# ATSAMRH707F18A register map
Vendor: Microchip Technology; Series: SAMRH707; File version: 0
CPU: CM7 r1p1, little endian, MPU, FPU, 3 interrupt priority bits
Registers are 32-bit, read-write, reset 0x0 unless marked. A register's access mark holds for its fields unless they carry their own. Offsets are from the block's base; [hi:lo] are bit positions; {n}, {i} and the like mark numbered series; 'fields as' and 'values as' point back to an identical list.

## TCMECC
Base 0x40100400; register names take the prefix TCMECC_
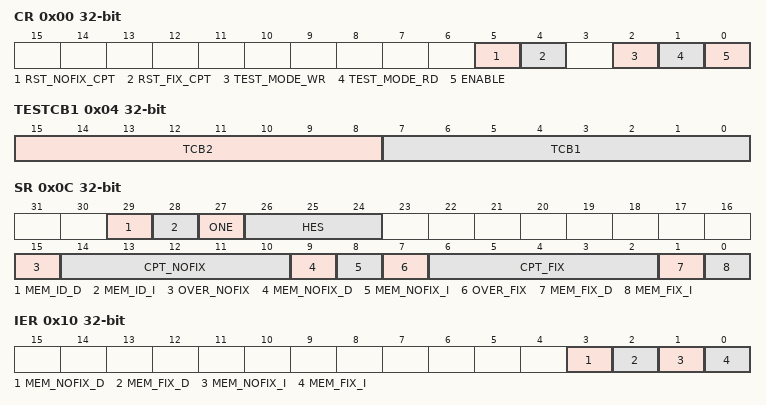
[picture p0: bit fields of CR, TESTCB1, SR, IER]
0x00 CR — TCMECC Control Register
  [5] RST_NOFIX_CPT — reset the un-fixable error counter
  [4] RST_FIX_CPT — reset the fixable error counter
  [2] TEST_MODE_WR — test mode of ECC protection - write mode
  [1] TEST_MODE_RD — test mode of ECC protection - read mode
  [0] ENABLE — ECC protection enable
0x04 TESTCB1 — TCMECC Test mode register 1
  [15:8] TCB2 — test check bit (8 bit)
  [7:0] TCB1 — test check bit (8 bit)
0x0C SR ro — TCMECC Status register
  [29] MEM_ID_D — memory identification number
  [28] MEM_ID_I — memory identification number
  [27] ONE
  [26:24] HES — Hardware Error Size
  [15] OVER_NOFIX — counter overflow
  [14:10] CPT_NOFIX — 5 bits counter
  [9] MEM_NOFIX_D — Un-fixable error status in data memory
  [8] MEM_NOFIX_I — Un-fixable error status in instruction memory
  [7] OVER_FIX — counter overflow
  [6:2] CPT_FIX — 5 bits counter
  [1] MEM_FIX_D — Fixable error status in data memory
  [0] MEM_FIX_I — Fixable error status in instruction memory
0x10 IER wo — TCMECC Interrupt Enable Register
  [3] MEM_NOFIX_D — Un-fixable error on data
  [2] MEM_FIX_D — Fixable error on data
  [1] MEM_NOFIX_I — Un-fixable error on instruction
  [0] MEM_FIX_I — Fixable error on instruction
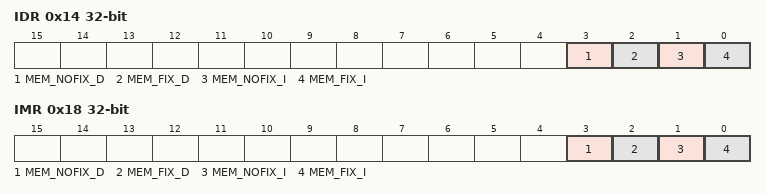
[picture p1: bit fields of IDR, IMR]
0x14 IDR wo — TCMECC Interrupt Disable Register
  [3] MEM_NOFIX_D — un-fixable error on data
  [2] MEM_FIX_D — fixable error on data
  [1] MEM_NOFIX_I — un-fixable error on instruction
  [0] MEM_FIX_I — fixable error on instruction
0x18 IMR ro — TCMECC Interrupt Mask Register
  fields as IDR
0x1C FAILAR ro — TCMECC Fail address register
  [31:0] ADDRESS — address of the error detected (refers to instruction memory)
0x20 FAILARD ro — TCMECC Fail address register data
  [31:0] ADDRESS — address of the error detected
0x24 FAILDR ro — TCMECC Fail data register
  [31:0] DATA — data of the error detected (refers to instruction memory)
0x28 FAILDRD ro — TCMECC Fail data register data
  fields as FAILDR

## TRNG — True Random Number Generator
Base 0x40090000; register names take the prefix TRNG_
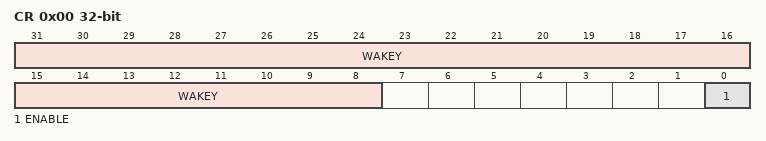
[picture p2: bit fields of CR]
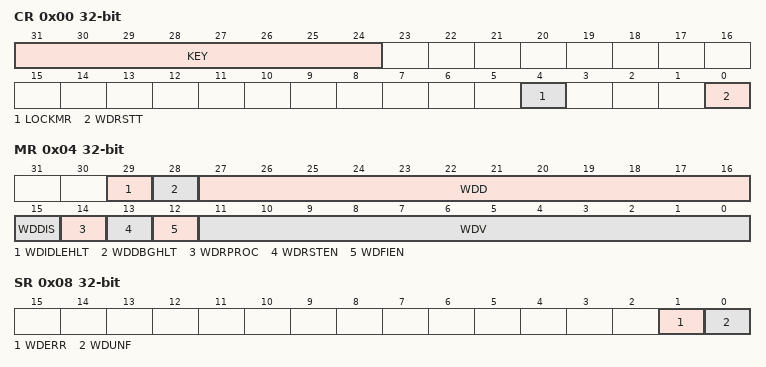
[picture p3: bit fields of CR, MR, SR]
0x00 CR wo — Control Register
  [31:8] WAKEY — Register Write Access Key
    0x524E47=PASSWD (Writing any other value in this field aborts the write operation.)
  [0] ENABLE — Enables the TRNG to Provide Random Values
0x10 IER wo — Interrupt Enable Register
  [0] DATRDY — Data Ready Interrupt Enable
0x14 IDR wo — Interrupt Disable Register
  [0] DATRDY — Data Ready Interrupt Disable
0x18 IMR ro — Interrupt Mask Register
  [0] DATRDY — Data Ready Interrupt Mask
0x1C ISR ro — Interrupt Status Register
  [0] DATRDY — Data Ready (cleared on read)
0x50 ODATA ro — Output Data Register
  [31:0] ODATA — Output Data

## WDT — Watchdog Timer
Base 0x40100250; register names take the prefix WDT_
0x00 CR wo — Control Register
  [31:24] KEY — Password
    165=PASSWD (Writing any other value in this field aborts the write operation.)
  [4] LOCKMR — Lock Mode Register Write Access
  [0] WDRSTT — Watchdog Restart
0x04 MR — Mode Register
  [29] WDIDLEHLT — Watchdog Idle Halt
  [28] WDDBGHLT — Watchdog Debug Halt
  [27:16] WDD — Watchdog Delta Value
  [15] WDDIS — Watchdog Disable
  [14] WDRPROC — Watchdog Reset Processor
  [13] WDRSTEN — Watchdog Reset Enable
  [12] WDFIEN — Watchdog Fault Interrupt Enable
  [11:0] WDV — Watchdog Counter Value
0x08 SR ro — Status Register
  [1] WDERR — Watchdog Error (cleared on read)
  [0] WDUNF — Watchdog Underflow (cleared on read)

## LOCKBIT
Base 0x00000000; register names take the prefix LOCKBIT_
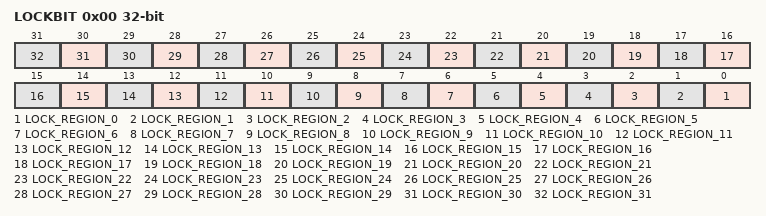
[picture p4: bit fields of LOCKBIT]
0x00 LOCKBIT — Lock Bits
  [n] LOCK_REGION_{n} (n=0..31)
